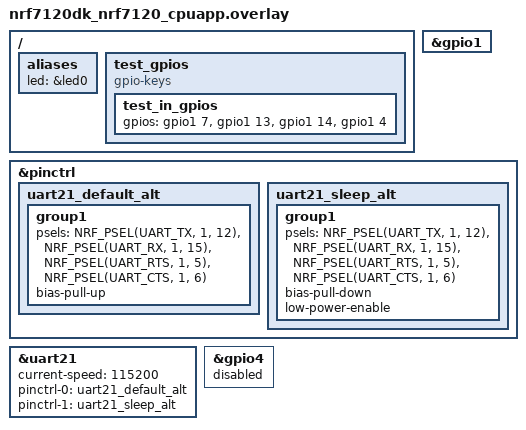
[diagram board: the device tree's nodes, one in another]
/*
 * Copyright (c) 2026 Nordic Semiconductor ASA
 *
 * SPDX-License-Identifier: LicenseRef-Nordic-5-Clause
 */

/*
 * Required loopbacks
 * P1.07 - P1.12
 * P1.13 - P1.15
 * P1.14 - P1.05
 * P1.04 - P1.06
 */

/ {
	aliases {
		led = &led0;
		/delete-property/ led1;
	};
};

/delete-node/ &led1;

/ {
	aliases {
		led = &led0;
		/delete-property/ led1;
	};

	test_gpios {
		compatible = "gpio-keys";

		test_in_gpios: test_in_gpios {
			gpios = <&gpio1 7 GPIO_ACTIVE_HIGH>, <&gpio1 13 GPIO_ACTIVE_HIGH>,
				<&gpio1 14 GPIO_ACTIVE_HIGH>, <&gpio1 4 GPIO_ACTIVE_HIGH>;
		};
	};
};

&gpio1 {
	status = "okay";
};

&pinctrl {
	uart21_default_alt: uart21_default_alt {
		group1 {
			psels = <NRF_PSEL(UART_TX, 1, 12)>,
				<NRF_PSEL(UART_RX, 1, 15)>,
				<NRF_PSEL(UART_RTS, 1, 5)>,
				<NRF_PSEL(UART_CTS, 1, 6)>;
			bias-pull-up;
		};
	};

	uart21_sleep_alt: uart21_sleep_alt {
		group1 {
			psels = <NRF_PSEL(UART_TX, 1, 12)>,
				<NRF_PSEL(UART_RX, 1, 15)>,
				<NRF_PSEL(UART_RTS, 1, 5)>,
				<NRF_PSEL(UART_CTS, 1, 6)>;
			bias-pull-down;
			low-power-enable;
		};
	};
};

dut: &uart21 {
	status = "okay";
	current-speed = <115200>;
	pinctrl-0 = <&uart21_default_alt>;
	pinctrl-1 = <&uart21_sleep_alt>;
	pinctrl-names = "default", "sleep";
	/delete-property/ zephyr,pm-device-runtime-auto;
};

&gpio4 {
	status = "disabled";
};
